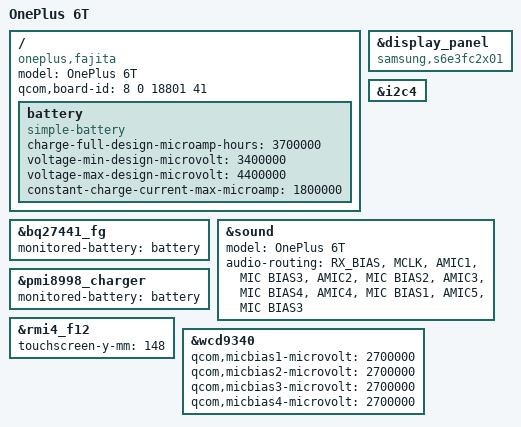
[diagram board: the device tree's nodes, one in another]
// SPDX-License-Identifier: GPL-2.0
/*
 * SDM845 OnePlus 6T (fajita) device tree.
 *
 * Copyright (c) 2020, The Linux Foundation. All rights reserved.
 */

#include "sdm845-oneplus-common.dtsi"

/ {
	model = "OnePlus 6T";
	compatible = "oneplus,fajita", "qcom,sdm845";
	qcom,board-id = <8 0 18801 41>;

	battery: battery {
		compatible = "simple-battery";

		charge-full-design-microamp-hours = <3700000>;
		voltage-min-design-microvolt = <3400000>;
		voltage-max-design-microvolt = <4400000>;

		/*
		 * Typical designs have multiple charger ICs which can handle more
		 * current but the OnePlus 6/T do not, hence the lower limit. This
		 * does not apply when using the Dash Charger, however this is not
		 * yet supported.
		 */
		constant-charge-current-max-microamp = <1800000>;
	};
};

&display_panel {
	status = "okay";

	compatible = "samsung,s6e3fc2x01";
};

&i2c4 {
	/* nxp,tfa9894 @ 0x34 */
};

&bq27441_fg {
	monitored-battery = <&battery>;
};

&sound {
	model = "OnePlus 6T";
	audio-routing = "RX_BIAS", "MCLK",
			"AMIC1", "MIC BIAS3",
			"AMIC2", "MIC BIAS2",
			"AMIC3", "MIC BIAS4",
			"AMIC4", "MIC BIAS1",
			"AMIC5", "MIC BIAS3";
};

&pmi8998_charger {
	monitored-battery = <&battery>;
};

/*
 * The TFA9894 codec is currently unsupported.
 * We need to delete the node to allow the soundcard
 * to probe for headphones/earpiece.
 */
/delete-node/ &speaker_playback_dai;

&rmi4_f12 {
	touchscreen-y-mm = <148>;
};

&wcd9340 {
	qcom,micbias1-microvolt = <2700000>;
	qcom,micbias2-microvolt = <2700000>;
	qcom,micbias3-microvolt = <2700000>;
	qcom,micbias4-microvolt = <2700000>;
};
